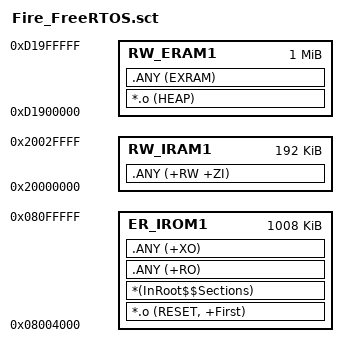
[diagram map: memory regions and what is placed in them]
; *************************************************************
; *** Scatter-Loading Description File generated by uVision ***
; *************************************************************

LR_IROM1 0x8004000 0x000FC000  {    ; load region size_region
  ER_IROM1 0x8004000 0x000FC000  {  ; load address = execution address
   *.o (RESET, +First)
   *(InRoot$$Sections)
   .ANY (+RO)
   .ANY (+XO)
  }
  RW_IRAM1 0x20000000 0x00030000  {  ; RW data
   .ANY (+RW +ZI)
  }
  RW_ERAM1 0xD1900000 0x00100000 {  ; 外部SDRAM  //100000
  *.o (HEAP)          ;选择堆区
   .ANY (EXRAM)				;选择EXRAM节区

  }
}

